# smc_cla: IP-XACT component
VLNV tenstorrent.com:ocah:smc_cla:1.0

## Address spaces and blocks
smc_cla_mmap.smc_cla: base 'h0, range 'h4000, width 64

## Registers
Registers are 64-bit, read-write, reset 0x0 unless marked. A register's access mark holds for its fields unless they carry their own. Offsets are from the block's base; lines under a group give offsets from that group; [hi:lo] are bit positions; {n}, {i} and the like mark numbered series; 'fields as' and 'values as' point back to an identical list; <NAME> marks a mode.

## smc_cla_mmap.smc_cla — Composite debug (DFD) MMR aperture mapping the DST sink, funnel, CLA, and DST blocks that smc_dfd_wrap instantiates.
Base 0x00000000
0x00 dst_sink group
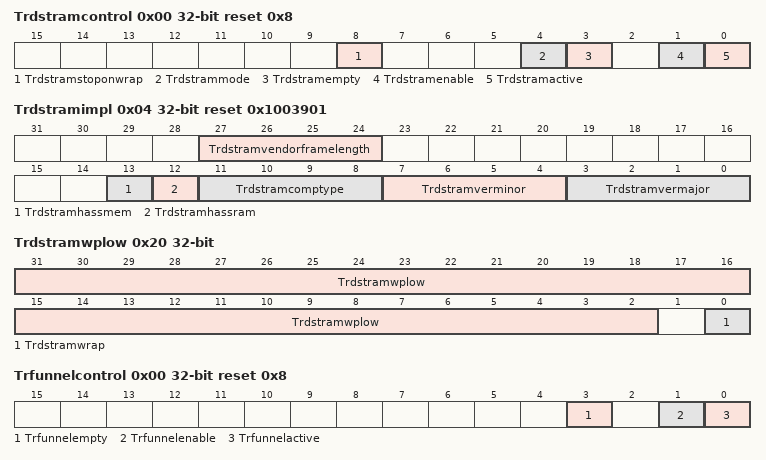
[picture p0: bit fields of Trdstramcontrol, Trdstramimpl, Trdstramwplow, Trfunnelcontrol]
  0x00 Trdstramcontrol 32-bit access per field reset 0x8
    [8] Trdstramstoponwrap rw, [4] Trdstrammode rw, [3] Trdstramempty ro, [1] Trdstramenable rw, [0] Trdstramactive rw
  0x04 Trdstramimpl 32-bit access per field reset 0x1003901
    [27:24] Trdstramvendorframelength rw — Frame length in 64-byte units. Only 1, 2, 4 and 8 (64, 128, 256 and 512 bytes) are supported, and the value must match the DST's trDstVendorFrameLength.
    [13] Trdstramhassmem ro
    [12] Trdstramhassram ro
    [11:8] Trdstramcomptype ro
    [7:4] Trdstramverminor ro
    [3:0] Trdstramvermajor ro
  0x10 Trdstramstartlow 32-bit access per field
    [31:2] Trdstramstartlow rw
  0x14 Trdstramstarthigh 32-bit
  0x18 Trdstramlimitlow 32-bit access per field
    [31:2] Trdstramlimitlow rw
  0x1C Trdstramlimithigh 32-bit
  0x20 Trdstramwplow 32-bit access per field
    [31:2] Trdstramwplow rw, [0] Trdstramwrap ro
  0x24 Trdstramwphigh 32-bit
  0x28 Trdstramrplow 32-bit access per field
    [31:2] Trdstramrplow rw — Read pointer, in 32-bit words; bits [31:2] of the byte address of the word the next trDstRamData read returns. Each trDstRamData read that returns unread data advances it by one word, and from trDstRamLimitLow it wraps to trDstRamStartLow.
  0x2C Trdstramrphigh 32-bit
  0x40 Trdstramdata 32-bit ro
    [31:0] Trdstramdata — Reading launches a trace-RAM read at trDstRamRPLow. When the RAM holds unread data, the read returns that 32-bit word and advances trDstRamRPLow; otherwise the pointer does not move.
  0xFF8 ScratchLo 32-bit — Scratch register (low) for DV and potential ECO usage
    [31:0] Data
  0xFFC ScratchHi 32-bit — Scratch register (high) for DV and potential ECO usage
    [31:0] Data
0x1000 funnel group
  0x00 Trfunnelcontrol 32-bit access per field reset 0x8
    [3] Trfunnelempty ro, [1] Trfunnelenable rw, [0] Trfunnelactive rw
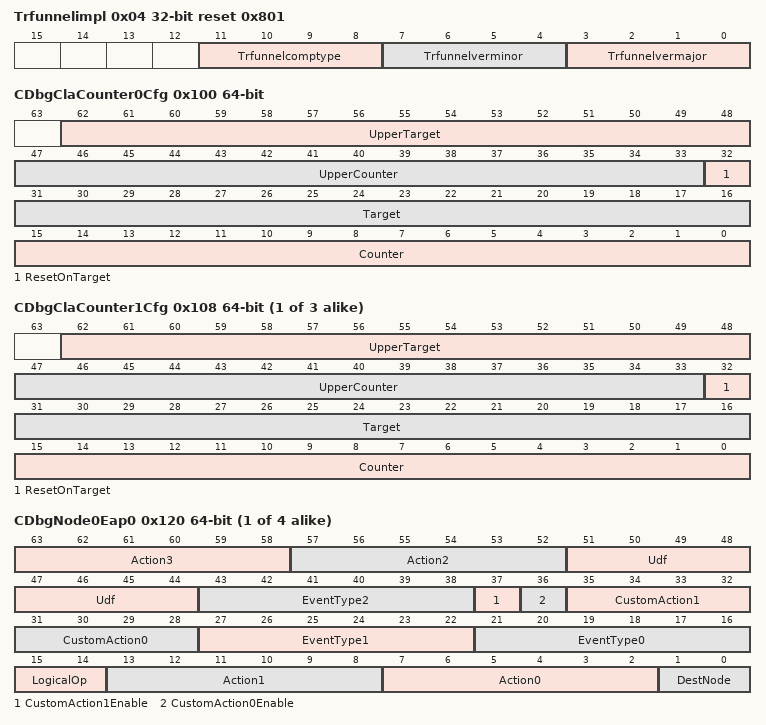
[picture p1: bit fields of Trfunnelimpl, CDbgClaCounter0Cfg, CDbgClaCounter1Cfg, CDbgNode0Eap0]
  0x04 Trfunnelimpl 32-bit ro reset 0x801
    [11:8] Trfunnelcomptype
    [7:4] Trfunnelverminor — e
    [3:0] Trfunnelvermajor
  0x08 Trfunneldisinput 32-bit
    [15:0] Trfunneldisinput — Bits 7:0 are reserved for N-trace srcs and 15:8 for Dst sources
  0xFF8 ScratchLo 32-bit — Scratch register (low) for DV and potential ECO usage
    [31:0] Data
  0xFFC ScratchHi 32-bit — Scratch register (high) for DV and potential ECO usage
    [31:0] Data
0x2000 cla group
  0x100 CDbgClaCounter0Cfg — Configure CLA counter0. One of the 4 counters used for counting cycles after a event match, and trigger a action on match.
    [62:48] UpperTarget
    [47:33] UpperCounter
    [32] ResetOnTarget — When Counter = {upper_target,target} reset to 0. With this bit set, counter will provide a periodic tick w/ frequency of (target +1) if the action is set to Auto Incr. The periodic tick will continue till Stop Auto Incr or Clear Counter action.
    [31:16] Target
    [15:0] Counter
  {0x100+8j} CDbgClaCounter{j}Cfg (j=1..3) — Configure CLA counter{j}. One of the 4 counters used for counting cycles after a event match, and trigger a action on match.
    [62:48] UpperTarget
    [47:33] UpperCounter
    [32] ResetOnTarget — When Counter = {upper_target,target}, reset to 0. With this bit set, counter will provide a periodic tick w/ frequency of (target +1) if the action is set to Auto Incr. The periodic tick will continue till Stop Auto Incr or Clear Counter action.
    [31:16] Target
    [15:0] Counter
  {0x120+0x10*j} CDbgNode{j}Eap0 (j=0..3) — CLA Action(s) are tied to events(s) using "event-action pairing" registers. One of the 16 EAPs (4 EAPs per Node, 4 Nodes).
    [63:58] Action3 — Select an Action
    [57:52] Action2 — Select an Action
    [51:44] Udf — User Defined Function with event type 0, 1, and 2 as arguments
    [43:38] EventType2 — Select a trigger event
    [37] CustomAction1Enable — custom_action1 is valid only if custom_action1_enable is set
    [36] CustomAction0Enable — custom_action0 is valid only if custom_action0_enable is set
    [35:32] CustomAction1 — Select the bit position of custom action bus to be set when EAP trigger is met. External blocks can define and implement the specific action for a given bit.
    [31:28] CustomAction0 — Select the bit position of custom action bus to be set when EAP trigger is met. External blocks can define and implement the specific action for a given bit.
    [27:22] EventType1 — Select a trigger event
    [21:16] EventType0 — Select a trigger event
    [15:14] LogicalOp — Relation to be satisfied among events to activate the actions
    [13:8] Action1 — Select an Action
    [7:2] Action0 — Select an Action
    [1:0] DestNode — Select Destination Node
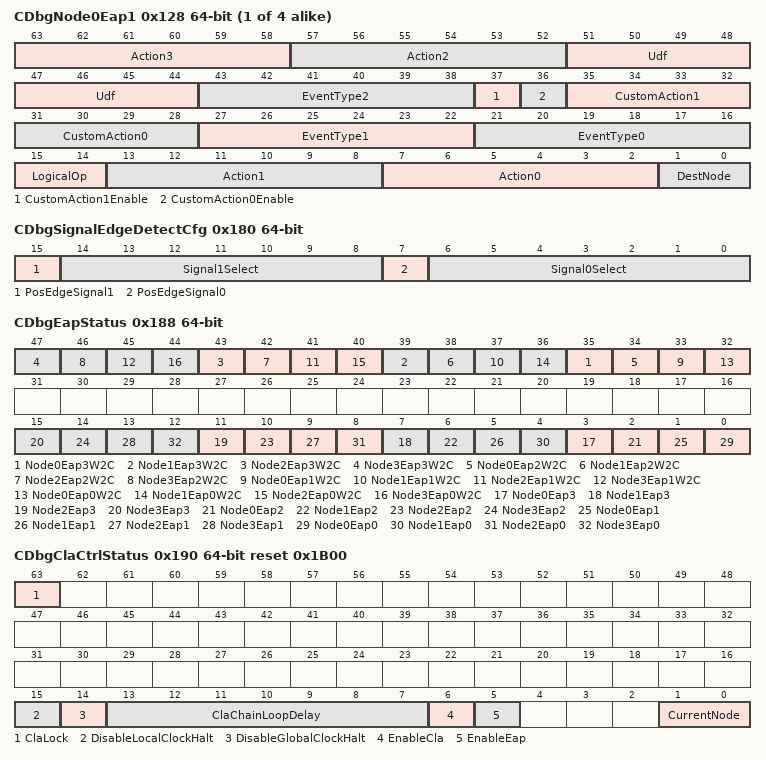
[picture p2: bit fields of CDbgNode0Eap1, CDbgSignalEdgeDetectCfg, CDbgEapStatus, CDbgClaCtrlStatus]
  {0x128+0x10*j} CDbgNode{j}Eap1 (j=0..3) — CLA Action(s) are tied to events(s) using "event-action pairing" registers. One of the 16 EAPs (4 EAPs per Node, 4 Nodes).
    fields as cla.CDbgNode0Eap0
  0x160 CDbgSignalMask0Lo — Used to define debug bus match events. The positive match event (0x2) fires when debug_bus & mask = match; the negative match event (0x3) fires when debug_bus & mask != match.
    [63:0] Value — Mask to be applied to debug bus before match
  0x168 CDbgSignalMatch0Lo — Used to define debug bus match events. The positive match event (0x2) fires when debug_bus & mask = match; the negative match event (0x3) fires when debug_bus & mask != match.
    [63:0] Value — Value used for debug bus match.
  0x170 CDbgSignalMask1Lo — Used to define debug bus match events. The positive match event (0x4) fires when debug_bus & mask = match; the negative match event (0x5) fires when debug_bus & mask != match.
    [63:0] Value — Mask to be applied to debug bus before match
  0x178 CDbgSignalMatch1Lo — Used to define debug bus match events. The positive match event (0x4) fires when debug_bus & mask = match; the negative match event (0x5) fires when debug_bus & mask != match.
    [63:0] Value — Value used for debug bus match.
  0x180 CDbgSignalEdgeDetectCfg — Register to configure debug bus for edge triggers.
    [15] PosEdgeSignal1 — Defines which edge to detect for singal from signal1_select. 1: Pos edge, 0: Neg Edge
    [14:8] Signal1Select — Define which signal to select for edge detection.
    [7] PosEdgeSignal0 — Defines which edge to detect for singal from signal0_select. 1: Pos edge, 0: Neg Edge
    [6:0] Signal0Select — Define which signal to select for edge detection.
  0x188 CDbgEapStatus access per field — Register to indicate if an EAP was activated. There is one status bit per EAP in bits [15:0] (Node0Eap0..Node3Eap3, 4 EAPs per Node across 4 Nodes) and one write-to-clear bit per EAP in bits [47:32] (Node0Eap0W2C..Node3Eap3W2C); write the matching w2c bit to reset a status bit. The register is used by SW to know if an action was taken (ex: NMI ISR needs to know which of the EAP triggered the NMI)
    [4n+35] Node{n}Eap3W2C rw (n=0..3), [4n+34] Node{n}Eap2W2C rw (n=0..3), [4n+33] Node{n}Eap1W2C rw (n=0..3), [4n+32] Node{n}Eap0W2C rw (n=0..3), [4n+3] Node{n}Eap3 ro (n=0..3), [4n+2] Node{n}Eap2 ro (n=0..3), [4n+1] Node{n}Eap1 ro (n=0..3), [4n] Node{n}Eap0 ro (n=0..3)
  0x190 CDbgClaCtrlStatus access per field reset 0x1B00 — Ctrl/Status register to Enable EAP after EAP programming is complete, and read the current node.
    [63] ClaLock rw — If this bit is set, then CLA is locked and the enable_cla is latched forever
    [15] DisableLocalClockHalt rw — If this bit is set, clock halt action is not applied to local clocks
    [14] DisableGlobalClockHalt rw — If this bit is set, clock halt action is not applied to global clocks
    [13:7] ClaChainLoopDelay rw — Self-filter delay, in CLA clock cycles, for the CLA's own cross-triggers. When an EAP action drives cross-trigger output n, the CLA ignores incoming cross-trigger n for one cycle, ClaChainLoopDelay cycles later, so that its own trigger returning through the cross-trigger network does not retrigger it; with 0 it ignores the input in the same cycle. A further own trigger while the delay counts does not restart it. Incoming clock halt is not filtered.
    [6] EnableCla rw — Set this bit to 1 to enable the CLA functional clock; clear it to 0 to gate that clock (save pwr). The CLA register block runs on a clock whose functional enable is tied high, so this bit can still be written while the functional clock is gated
    [5] EnableEap rw — Set Enable EAP to 1 after EAP programming is complete
    [1:0] CurrentNode ro — Read the current node.
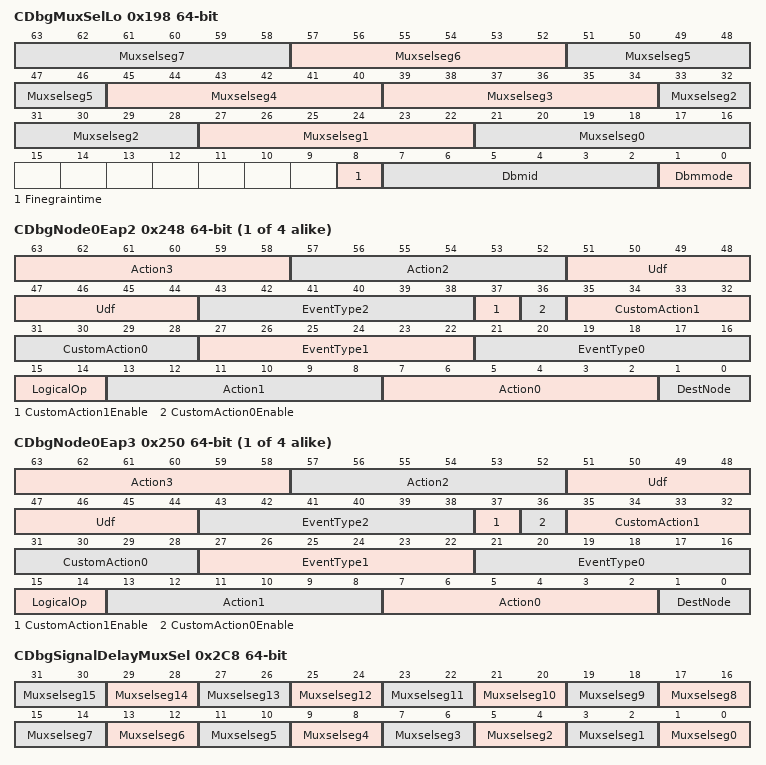
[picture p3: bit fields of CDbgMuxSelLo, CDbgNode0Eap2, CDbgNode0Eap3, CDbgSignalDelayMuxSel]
  0x198 CDbgMuxSelLo — Mode, ID, fine-grain time enable and lane selects for the CLA debug-bus mux, which builds the four 16-bit lanes of the CLA's 64-bit debug bus from 16 input segments. The mux ID is 0: the mode is taken while DbmId is 0, and the lane selects while DbmId is 0 and DbmMode is 1.
    [6n+21:6n+16] Muxselseg{n} (n=4..7) — No effect in the SMC: the CLA debug-bus mux has four output lanes, selected by Muxselseg0 to Muxselseg3.
    [39:34] Muxselseg3 — Binary segment select for lane 3 of the CLA debug bus, bits [63:48]. The input segments are 16 bits wide: Seg0 = input bits [15:0], Seg1 = [31:16], and so on to Seg15. 0 selects Seg3; a value k from 1 to 12 selects Seg(k+3), so 1 selects Seg4 and 4 selects Seg7; 13 to 63 drive zero. When FineGrainTime is set, the fine-grain time counter is inserted below Seg0: 0 selects Seg2, and k from 1 to 13 selects Seg(k+2).
    [33:28] Muxselseg2 — Binary segment select for lane 2 of the CLA debug bus, bits [47:32]. The input segments are 16 bits wide: Seg0 = input bits [15:0], Seg1 = [31:16], and so on to Seg15. 0 selects Seg2; a value k from 1 to 12 selects Seg(k+3), so 1 selects Seg4 and 4 selects Seg7; 13 to 63 drive zero. When FineGrainTime is set, the fine-grain time counter is inserted below Seg0: 0 selects Seg1, and k from 1 to 13 selects Seg(k+2).
    [27:22] Muxselseg1 — Binary segment select for lane 1 of the CLA debug bus, bits [31:16]. The input segments are 16 bits wide: Seg0 = input bits [15:0], Seg1 = [31:16], and so on to Seg15. 0 selects Seg1; a value k from 1 to 12 selects Seg(k+3), so 1 selects Seg4 and 4 selects Seg7; 13 to 63 drive zero. When FineGrainTime is set, the fine-grain time counter is inserted below Seg0: 0 selects Seg0, and k from 1 to 13 selects Seg(k+2).
    [21:16] Muxselseg0 — Binary segment select for lane 0 of the CLA debug bus, bits [15:0]. The input segments are 16 bits wide: Seg0 = input bits [15:0], Seg1 = [31:16], and so on to Seg15. 0 selects Seg0; a value k from 1 to 12 selects Seg(k+3), so 1 selects Seg4 and 4 selects Seg7; 13 to 63 drive zero. When FineGrainTime is set, the fine-grain time counter is inserted below Seg0: 0 selects the fine-grain time counter, and k from 1 to 13 selects Seg(k+2).
    [8] Finegraintime — Fine Grain Time Enable. If this bit is set, the fine grain time is enabled.
    [7:2] Dbmid — Unique DBM ID of the DBM instance
    [1:0] Dbmmode — Mode selection, 0: DBM off, 1: Normal debug mode, 2: DBM ID output mode, 3: Toggle Mode
  0x1A0 CDbgRsvd1 — Reserved Register that can be changed.
    [63:0] Value — Value of reserved register.
  0x1A8 CDbgRsvd2 — Reserved Register that can be changed.
    [63:0] Value — Value of reserved register.
  0x1B0 CDbgTransitionMaskLo — 3 registers to configure "transition event". This register is to select the signals of interest using a mask.
    [63:0] Value
  0x1B8 CDbgTransitionFromValueLo — 3 registers to configure "transition event". The event is triggered on transition from Value A to Value B. This register specifies Value A.
    [63:0] Value
  0x1C0 CDbgTransitionToValueLo — 3 registers to configure "transition event". The event is triggered on transition from Value A to Value B. This register specifies Value B.
    [63:0] Value
  0x1C8 CDbgOnesCountMaskLo — 2 registers to configure "ones count" event. This register is to select the signals of interest using a mask.
    [63:0] Value
  0x1D0 CDbgOnesCountValue — 2 registers to configure "ones count" event. Event triggered when the sum of the signals match the value specified in this register.
    [63:0] Value
  0x1D8 CDbgAnyChangeLo — Event triggered when a subset of debug signals change. The mask is used to select the subset of the debug signals.
    [63:0] Mask
  {0x1E0+0x10*j} CDbgSignalSnapshotNode{j}Eap0Lo ro (j=0..3) — debug Bus Value when Node{j} Eap0 Trigger is met.
    [63:0] Value
  {0x1E8+0x10*j} CDbgSignalSnapshotNode{j}Eap1Lo ro (j=0..3) — debug Bus Value when Node{j} Eap1 Trigger is met.
    [63:0] Value
  0x220 CDbgClaTimeMatch — This value is compared (greater than or equal to the programmed value) against the internal time register value of the core, and is used to generate a time match event for CLA. Needs to be non zero for the time match event signal to trigger. The event will only trigger an action if the EAP programming is done. Requires writing 0 to this register to stop the match event.
    [63:0] TimeMatchVal
  0x228 CDbgSignalMask2Lo — Used to define debug bus match events. The positive match event (0x1C) fires when debug_bus & mask = match; the negative match event (0x1D) fires when debug_bus & mask != match.
    [63:0] Value — Mask to be applied to debug bus before match
  0x230 CDbgSignalMatch2Lo — Used to define debug bus match events. The positive match event (0x1C) fires when debug_bus & mask = match; the negative match event (0x1D) fires when debug_bus & mask != match.
    [63:0] Value — Value used for debug bus match.
  0x238 CDbgSignalMask3Lo — Used to define debug bus match events. The positive match event (0x1E) fires when debug_bus & mask = match; the negative match event (0x1F) fires when debug_bus & mask != match.
    [63:0] Value — Mask to be applied to debug bus before match
  0x240 CDbgSignalMatch3Lo — Used to define debug bus match events. The positive match event (0x1E) fires when debug_bus & mask = match; the negative match event (0x1F) fires when debug_bus & mask != match.
    [63:0] Value — Value used for debug bus match.
  {0x248+0x10*j} CDbgNode{j}Eap2 (j=0..3) — CLA Action(s) are tied to events(s) using "event-action pairing" registers. One of the 16 EAPs (4 EAPs per Node, 4 Nodes).
    fields as cla.CDbgNode0Eap0
  {0x250+0x10*j} CDbgNode{j}Eap3 (j=0..3) — CLA Action(s) are tied to events(s) using "event-action pairing" registers. One of the 16 EAPs (4 EAPs per Node, 4 Nodes).
    fields as cla.CDbgNode0Eap0
  {0x288+0x10*j} CDbgSignalSnapshotNode{j}Eap2Lo ro (j=0..3) — debug Bus Value when Node{j} Eap2 Trigger is met.
    [63:0] Value
  {0x290+0x10*j} CDbgSignalSnapshotNode{j}Eap3Lo ro (j=0..3) — debug Bus Value when Node{j} Eap3 Trigger is met.
    [63:0] Value
  0x2C8 CDbgSignalDelayMuxSel
    [2n+1:2n] Muxselseg{n} (n=8..15) — Dbg Mux Shifted signals Select Bits for Lane 0
    [2n+1:2n] Muxselseg{n} (n=0..7) — Dbg Mux Shifted signals Select Bits for Lane {n}
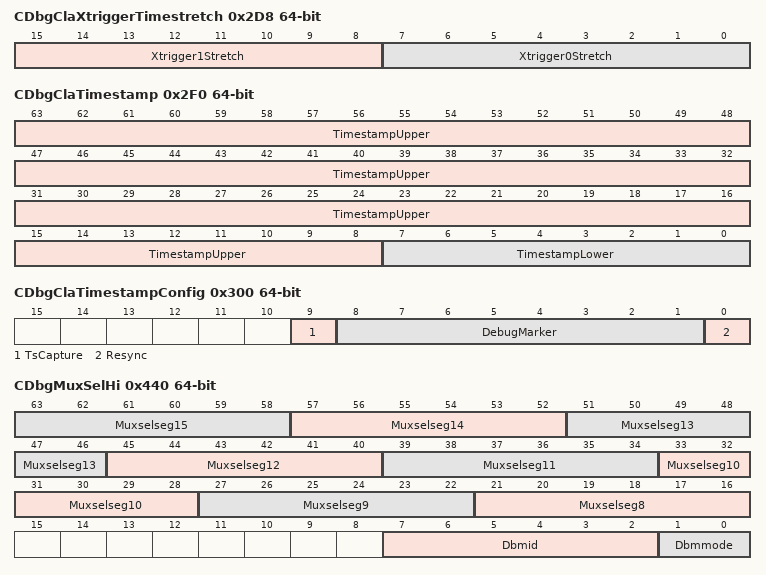
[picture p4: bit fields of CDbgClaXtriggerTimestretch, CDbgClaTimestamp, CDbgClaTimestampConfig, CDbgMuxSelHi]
  0x2D8 CDbgClaXtriggerTimestretch — This value determines the time stretched pulse duration for the cross trigger. 8 bits for each of the two triggers.
    [15:8] Xtrigger1Stretch, [7:0] Xtrigger0Stretch
  0x2F0 CDbgClaTimestamp — 64-bit timestamp counter. Increments on time_tick. Can be written directly or loaded from timestamp_sync on xtrigger when resync is enabled.
    [63:8] TimestampUpper — Current timestamp value (upper 56 bits)
    [7:0] TimestampLower — Current timestamp value (lower 8 bits)
  0x2F8 CDbgClaTimestampSync — Timestamp sync value. This value is loaded into the timestamp register on xtrigger posedge when resync bit is enabled.
    [63:0] TimestampSync — Sync value to load into timestamp
  0x300 CDbgClaTimestampConfig — Timestamp configuration register. Controls resync behavior and debug marker.
    [9] TsCapture — When this bit is set, a cross trigger 0 event will cause the value from Timestamp register to be written into the TimestampCapture register. No effect in the SMC, where the CLA timestamp counts the local time tick (timestamp scheme 0).
    [8:1] DebugMarker — Debug marker output value
    [0] Resync — When set, timestamp is loaded from timestamp_sync on xtrigger posedge. Auto-clears after load.
  0x308 CDbgClaTimestampOffset — Timestamp offset register. The Offset value is subtracted from the timestamp before comparing with incoming timestamp value. No effect in the SMC, where the CLA timestamp counts the local time tick (timestamp scheme 0).
    [55:0] Offset — Timestamp offset value. No effect in the SMC.
  0x400 CDbgSignalMask0Hi — Used to define debug bus match events. The positive match event (0x2) fires when debug_bus & mask = match; the negative match event (0x3) fires when debug_bus & mask != match. No effect in the SMC, whose CLA evaluates a 64-bit debug bus; only the Lo register is used.
    [63:0] Value — Mask to be applied to debug bus before match
  0x408 CDbgSignalMatch0Hi — Used to define debug bus match events. The positive match event (0x2) fires when debug_bus & mask = match; the negative match event (0x3) fires when debug_bus & mask != match. No effect in the SMC, whose CLA evaluates a 64-bit debug bus; only the Lo register is used.
    [63:0] Value — Value used for debug bus match.
  0x410 CDbgSignalMask1Hi — Used to define debug bus match events. The positive match event (0x4) fires when debug_bus & mask = match; the negative match event (0x5) fires when debug_bus & mask != match. No effect in the SMC, whose CLA evaluates a 64-bit debug bus; only the Lo register is used.
    [63:0] Value — Mask to be applied to debug bus before match
  0x418 CDbgSignalMatch1Hi — Used to define debug bus match events. The positive match event (0x4) fires when debug_bus & mask = match; the negative match event (0x5) fires when debug_bus & mask != match. No effect in the SMC, whose CLA evaluates a 64-bit debug bus; only the Lo register is used.
    [63:0] Value — Value used for debug bus match.
  0x420 CDbgSignalMask2Hi — Used to define debug bus match events. The positive match event (0x1C) fires when debug_bus & mask = match; the negative match event (0x1D) fires when debug_bus & mask != match. No effect in the SMC, whose CLA evaluates a 64-bit debug bus; only the Lo register is used.
    [63:0] Value — Mask to be applied to debug bus before match
  0x428 CDbgSignalMatch2Hi — Used to define debug bus match events. The positive match event (0x1C) fires when debug_bus & mask = match; the negative match event (0x1D) fires when debug_bus & mask != match. No effect in the SMC, whose CLA evaluates a 64-bit debug bus; only the Lo register is used.
    [63:0] Value — Value used for debug bus match.
  0x430 CDbgSignalMask3Hi — Used to define debug bus match events. The positive match event (0x1E) fires when debug_bus & mask = match; the negative match event (0x1F) fires when debug_bus & mask != match. No effect in the SMC, whose CLA evaluates a 64-bit debug bus; only the Lo register is used.
    [63:0] Value — Mask to be applied to debug bus before match
  0x438 CDbgSignalMatch3Hi — Used to define debug bus match events. The positive match event (0x1E) fires when debug_bus & mask = match; the negative match event (0x1F) fires when debug_bus & mask != match. No effect in the SMC, whose CLA evaluates a 64-bit debug bus; only the Lo register is used.
    [63:0] Value — Value used for debug bus match.
  0x440 CDbgMuxSelHi — No effect in the SMC. The CLA debug-bus mux has four output lanes and takes its mode, ID, fine-grain time enable and lane selects from CDbgMuxSelLo.
    [6n-27:6n-32] Muxselseg{n} (n=8..15) — No effect in the SMC.
    [7:2] Dbmid — No effect in the SMC.
    [1:0] Dbmmode — No effect in the SMC.
  0x448 CDbgTransitionMaskHi — 3 registers to configure "transition event". This register is to select the signals of interest using a mask. No effect in the SMC, whose CLA evaluates a 64-bit debug bus; only the Lo register is used.
    [63:0] Value
  0x450 CDbgTransitionFromValueHi — 3 registers to configure "transition event". The event is triggered on transition from Value A to Value B. This register specifies Value A. No effect in the SMC, whose CLA evaluates a 64-bit debug bus; only the Lo register is used.
    [63:0] Value
  0x458 CDbgTransitionToValueHi — 3 registers to configure "transition event". The event is triggered on transition from Value A to Value B. This register specifies Value B. No effect in the SMC, whose CLA evaluates a 64-bit debug bus; only the Lo register is used.
    [63:0] Value
  0x460 CDbgOnesCountMaskHi — 2 registers to configure "ones count" event. This register is to select the signals of interest using a mask. No effect in the SMC, whose CLA evaluates a 64-bit debug bus; only the Lo register is used.
    [63:0] Value
  0x468 CDbgAnyChangeHi — Event triggered when a subset of debug signals change. The mask is used to select the subset of the debug signals. No effect in the SMC, whose CLA evaluates a 64-bit debug bus; only the Lo register is used.
    [63:0] Mask
  {0x470+0x10*j} CDbgSignalSnapshotNode{j}Eap0Hi ro (j=0..3) — debug Bus Value when Node{j} Eap0 Trigger is met. Never captured in the SMC, whose CLA evaluates a 64-bit debug bus.
    [63:0] Value
  {0x478+0x10*j} CDbgSignalSnapshotNode{j}Eap1Hi ro (j=0..3) — debug Bus Value when Node{j} Eap1 Trigger is met. Never captured in the SMC, whose CLA evaluates a 64-bit debug bus.
    [63:0] Value
  {0x4B0+0x10*j} CDbgSignalSnapshotNode{j}Eap2Hi ro (j=0..3) — debug Bus Value when Node{j} Eap2 Trigger is met. Never captured in the SMC, whose CLA evaluates a 64-bit debug bus.
    [63:0] Value
  {0x4B8+0x10*j} CDbgSignalSnapshotNode{j}Eap3Hi ro (j=0..3) — debug Bus Value when Node{j} Eap3 Trigger is met. Never captured in the SMC, whose CLA evaluates a 64-bit debug bus.
    [63:0] Value
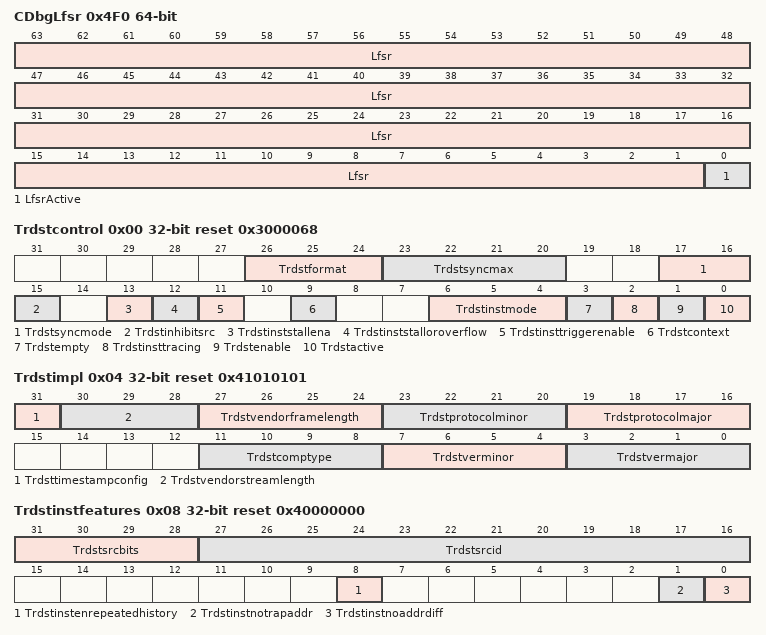
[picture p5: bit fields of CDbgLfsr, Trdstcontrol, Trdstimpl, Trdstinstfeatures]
  0x4F0 CDbgLfsr — LFSR value.
    [63:1] Lfsr — Value of the LFSR register.
    [0] LfsrActive — Enable the LFSR register.
  0x4F8 CDbgLfsrMask — LFSR programming mask.
    [63:1] Mask — Value to mask the LFSR register.
  0x500 CDbgTimestampCapture ro — Captured timestamp upper bits. When ts_capture is set in the timestamp config register, a cross trigger 0 event captures the timestamp upper bits into this register. Never captured in the SMC, where the CLA timestamp counts the local time tick (timestamp scheme 0).
    [63:0] Timestamp — Timestamp capture value.
  {0x508+0x10*j} CDbgCompare{j}Lo (j=0..3) — Value for arithmetic comparison.
    [63:0] Value
  {0x510+0x10*j} CDbgCompare{j}MaskLo (j=0..3) — Value to mask the arithmetic comparison.
    [63:0] Value
  {0x548+0x10*j} CDbgCompare{j}Hi (j=0..3) — Value for arithmetic comparison. No effect in the SMC, whose CLA evaluates a 64-bit debug bus; only the Lo register is used.
    [63:0] Value — Value for arithmetic comparison.
  {0x550+0x10*j} CDbgCompare{j}MaskHi (j=0..3) — Value to mask the arithmetic comparison. No effect in the SMC, whose CLA evaluates a 64-bit debug bus; only the Lo register is used.
    [63:0] Value — Value to mask the arithmetic comparison.
  0xFF8 Scratch — Additional scratch register for DV and potential ECO usage
    [63:0] Data
0x3000 dst group
  0x00 Trdstcontrol 32-bit access per field reset 0x3000068
    [26:24] Trdstformat rw — bit[0]: XOR Enable, bit[1]: VLT Enable. Supported values : 2'b3 (XOR+VLT Compression), 2'b1 (XOR Compresion), 2'b0 (No Compression)
    [23:20] Trdstsyncmax rw — When trDstSyncMode is set to 2'b10, timestamp will be sent for every 2^(trDstSyncMax + 4) Cluster clocks.
    [17:16] Trdstsyncmode rw — Periodic sync mode. 2'b00: off. 2'b01: stream counting, with trDstVendorStreamLength frames between non-compressed packets. 2'b10: send a timestamp packet every 2^(trDstSyncMax + 4) Cluster clocks. 2'b11: no effect, as 2'b00.
    [15] Trdstinhibitsrc ro
    [13] Trdstinststallena ro
    [12] Trdstinststalloroverflow ro
    [11] Trdstinsttriggerenable rw
    [9] Trdstcontext ro
    [6:4] Trdstinstmode ro
    [3] Trdstempty ro
    [2] Trdstinsttracing rw
    [1] Trdstenable rw
    [0] Trdstactive rw
  0x04 Trdstimpl 32-bit access per field reset 0x41010101
    [31] Trdsttimestampconfig rw — DST timestamp configuration. 0: timestamp input form external source (CoreTime). 1: timestamp from CLA timesync.
    [30:28] Trdstvendorstreamlength rw — Specify Stream length. A stream starts with "no compressed packet". Stream length specifies number of frames before a non-compressed packet is sent, and applies only when trDstSyncMode is 2'b01. Values 0 to 4 give Stream Length = 32* 2^trDstVendorStreamLength (32 to 512 frames); values 5 to 7 give 32.
    [27:24] Trdstvendorframelength rw — Specify frame length. Frame Length = trDstVendorFrameLength* 64 bytes; Frame Length should be a multiple of Bank Data Width. Only 1, 2, 4 and 8 (64, 128, 256 and 512 bytes) are supported, because the DST sink finds frame boundaries at the power of two given by the highest set bit of its frame length. Program the sink's trDstRamVendorFrameLength with the same value.
    [23:20] Trdstprotocolminor ro
    [19:16] Trdstprotocolmajor ro
    [11:8] Trdstcomptype ro
    [7:4] Trdstverminor ro
    [3:0] Trdstvermajor ro
  0x08 Trdstinstfeatures 32-bit access per field reset 0x40000000
    [31:28] Trdstsrcbits rw
    [27:16] Trdstsrcid rw — Source ID sent in the trace packet headers. Only bits [3:0] are used.
    [8] Trdstinstenrepeatedhistory ro
    [1] Trdstinstnotrapaddr ro
    [0] Trdstinstnoaddrdiff ro
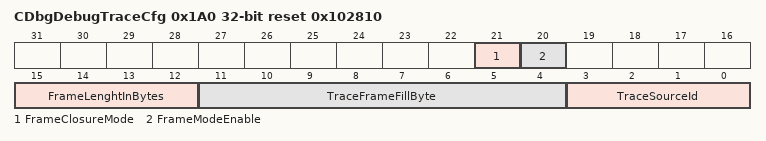
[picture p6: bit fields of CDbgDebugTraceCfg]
  0x1A0 CDbgDebugTraceCfg 32-bit reset 0x102810
    [21] FrameClosureMode — Closure Mode: 1: Close frame with a packet no larger than max packet size before any overflow (due to packets crossing frame boundary). 0: Close frame when packets cross boundary. Push back packet crossing frame boundary to packet generator.
    [20] FrameModeEnable — Enable Frame Mode (Frame Mode: Always pack "frame length" number of bytes for trace transmission). If flush to memory is stalled (due to silicon bug), we can have incomplete packets in memory. Frame Mode will help SW decoder to avoid reading incomplete trasnmitted packets. In Frame Mode, SW will get a memory pointer that is aligned to Frame Length. HW will ensure there are no incomplete packets incluced in the region pointed by memory pointer.
    [15:12] FrameLenghtInBytes — Use trDstImpl[trDstVendorFrameLength] for Frame Length programming. Register field ZBB-ed.
    [11:4] TraceFrameFillByte — Use "Filler Packet" to align a stream of trace packets within a frame boundary.
    [3:0] TraceSourceId — Stored but not used. The trace packet headers carry trDstInstFeatures[trDstSrcID].
  0xFF8 ScratchLo 32-bit — Scratch register (low) for DV and potential ECO usage
    [31:0] Data
  0xFFC ScratchHi 32-bit — Scratch register (high) for DV and potential ECO usage
    [31:0] Data

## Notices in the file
SPDX-License-Identifier: Apache-2.0
SPDX-FileCopyrightText: 2026 Tenstorrent USA, Inc.
